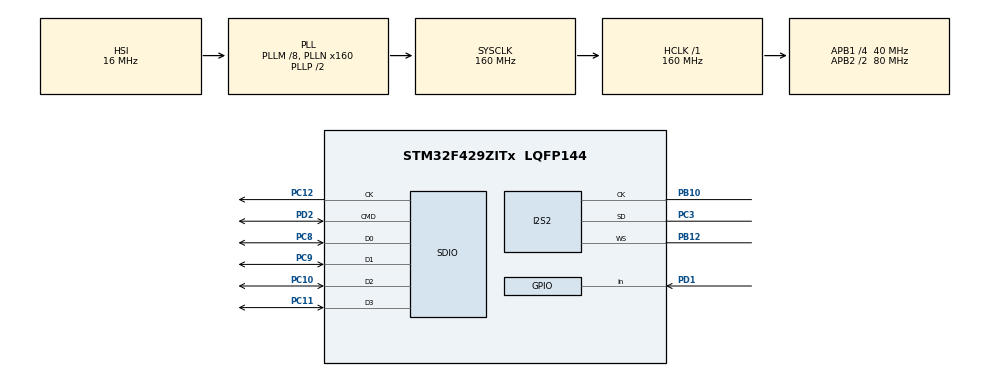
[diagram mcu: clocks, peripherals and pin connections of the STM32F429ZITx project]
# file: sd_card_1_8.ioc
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Dma.Request0=SPI2_RX
Dma.SPI2_RX.0.Direction=DMA_PERIPH_TO_MEMORY
Dma.SPI2_RX.0.FIFOMode=DMA_FIFOMODE_DISABLE
Dma.SPI2_RX.0.Instance=DMA1_Stream3
Dma.SPI2_RX.0.MemDataAlignment=DMA_MDATAALIGN_HALFWORD
Dma.SPI2_RX.0.MemInc=DMA_MINC_ENABLE
Dma.SPI2_RX.0.Mode=DMA_CIRCULAR
Dma.SPI2_RX.0.PeriphDataAlignment=DMA_PDATAALIGN_HALFWORD
Dma.SPI2_RX.0.PeriphInc=DMA_PINC_DISABLE
Dma.SPI2_RX.0.Priority=DMA_PRIORITY_LOW
FATFS.BSP.number=1
FATFS.USE_DMA_CODE_SD=0
FATFS._MAX_SS=2048
FATFS0.BSP.STBoard=false
FATFS0.BSP.api=Unknown
FATFS0.BSP.i2caddr=0
FATFS0.BSP.instance=PD1
FATFS0.BSP.ip=GPIO
FATFS0.BSP.mode=Input
FATFS0.BSP.name=Detect_SDIO
FATFS0.BSP.solution=PD1
I2S2.AudioFreq=I2S_AUDIOFREQ_32K
I2S2.DataFormat=I2S_DATAFORMAT_16B_EXTENDED
I2S2.ErrorAudioFreq=-0.26 %
I2S2.FullDuplexMode=I2S_FULLDUPLEXMODE_DISABLE
I2S2.Instance=SPI$Index
I2S2.Mode=I2S_MODE_MASTER_RX
I2S2.RealAudioFreq=31.914 KHz
I2S2.VirtualMode=I2S_MODE_MASTER
Mcu.Family=STM32F4
Mcu.Name=STM32F429ZITx
Mcu.Package=LQFP144
NVIC.DMA1_Stream3_IRQn=true\:0\:0\:false\:false\:true\:false\:true
NVIC.PriorityGroup=NVIC_PRIORITYGROUP_4
PB10.Mode=Half_Duplex_Master
PB10.Signal=I2S2_CK
PB12.Mode=Half_Duplex_Master
PB12.Signal=I2S2_WS
PC10.GPIO_PuPd=GPIO_PULLUP
PC10.Mode=SD_4_bits_Wide_bus
PC10.Signal=SDIO_D2
PC11.GPIO_PuPd=GPIO_PULLUP
PC11.Mode=SD_4_bits_Wide_bus
PC11.Signal=SDIO_D3
PC12.Mode=SD_4_bits_Wide_bus
PC12.Signal=SDIO_CK
PC3.Mode=Half_Duplex_Master
PC3.Signal=I2S2_SD
PC8.GPIO_PuPd=GPIO_PULLUP
PC8.Mode=SD_4_bits_Wide_bus
PC8.Signal=SDIO_D0
PC9.GPIO_PuPd=GPIO_PULLUP
PC9.Mode=SD_4_bits_Wide_bus
PC9.Signal=SDIO_D1
PD1.Signal=GPIO_Input
PD2.GPIO_PuPd=GPIO_PULLUP
PD2.Mode=SD_4_bits_Wide_bus
PD2.Signal=SDIO_CMD
ProjectManager.HeapSize=0x2000
ProjectManager.StackSize=0x4000
ProjectManager.TargetToolchain=STM32CubeIDE
RCC.48MHZClocksFreq_Value=45714285.71428572
RCC.AHBFreq_Value=160000000
RCC.APB1CLKDivider=RCC_HCLK_DIV4
RCC.APB1Freq_Value=40000000
RCC.APB1TimFreq_Value=80000000
RCC.APB2CLKDivider=RCC_HCLK_DIV2
RCC.APB2Freq_Value=80000000
RCC.APB2TimFreq_Value=160000000
RCC.CortexFreq_Value=160000000
RCC.HCLKFreq_Value=160000000
RCC.HSE_VALUE=8000000
RCC.HSI_VALUE=16000000
RCC.LSE_VALUE=32768
RCC.PLLM=8
RCC.PLLN=160
RCC.PLLQ=7
RCC.PLLSAIN=50
RCC.SYSCLKFreq_VALUE=160000000
RCC.SYSCLKSource=RCC_SYSCLKSOURCE_PLLCLK
RCC.VCOOutputFreq_Value=320000000
SDIO.ClockDiv=14
VP_FATFS_VS_SDIO.Mode=SDIO
board=STM32F429I-DISC1

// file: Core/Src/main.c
/* USER CODE BEGIN Header */
/**
  ******************************************************************************
  * @file           : main.c
  * @brief          : Main program body
  ******************************************************************************
  * @attention
  *
  * Copyright (c) 2023 STMicroelectronics.
  * All rights reserved.
  *
  * This software is licensed under terms that can be found in the LICENSE file
  * in the root directory of this software component.
  * If no LICENSE file comes with this software, it is provided AS-IS.
  *
  ******************************************************************************
  */
/* USER CODE END Header */
#include "main.h"
#include "fatfs.h"

/* USER CODE BEGIN Includes */
#include "stdio.h"
#include "audio_sd.h"
/* USER CODE END Includes */

I2S_HandleTypeDef hi2s2;
DMA_HandleTypeDef hdma_spi2_rx;

SD_HandleTypeDef hsd;

/* USER CODE BEGIN PV */
int16_t data_i2s[100];
volatile int16_t sample_i2s;
/* USER CODE END PV */

void SystemClock_Config(void);
static void MX_GPIO_Init(void);
static void MX_SDIO_SD_Init(void);
static void MX_DMA_Init(void);
static void MX_I2S2_Init(void);

int main(void)
{

  /* MCU Configuration--------------------------------------------------------*/

  /* Reset of all peripherals, Initializes the Flash interface and the Systick. */
  HAL_Init();

  /* Configure the system clock */
  SystemClock_Config();

  /* Initialize all configured peripherals */
  MX_GPIO_Init();
  MX_SDIO_SD_Init();
  MX_DMA_Init();
  MX_I2S2_Init();
  MX_FATFS_Init();
  /* USER CODE BEGIN 2 */
  HAL_I2S_Receive_DMA(&hi2s2, (uint8_t *)data_i2s, sizeof(data_i2s)/2);
  HAL_Delay(500);
  sd_card_init();
  /* USER CODE END 2 */

  /* Infinite loop */
  while (1)
  {

  }
}

void SystemClock_Config(void)
{
  RCC_OscInitTypeDef RCC_OscInitStruct = {0};
  RCC_ClkInitTypeDef RCC_ClkInitStruct = {0};

  /** Configure the main internal regulator output voltage
  */
  __HAL_RCC_PWR_CLK_ENABLE();
  __HAL_PWR_VOLTAGESCALING_CONFIG(PWR_REGULATOR_VOLTAGE_SCALE1);
  /** Initializes the RCC Oscillators according to the specified parameters
  * in the RCC_OscInitTypeDef structure.
  */
  RCC_OscInitStruct.OscillatorType = RCC_OSCILLATORTYPE_HSI;
  RCC_OscInitStruct.HSIState = RCC_HSI_ON;
  RCC_OscInitStruct.HSICalibrationValue = RCC_HSICALIBRATION_DEFAULT;
  RCC_OscInitStruct.PLL.PLLState = RCC_PLL_ON;
  RCC_OscInitStruct.PLL.PLLSource = RCC_PLLSOURCE_HSI;
  RCC_OscInitStruct.PLL.PLLM = 8;
  RCC_OscInitStruct.PLL.PLLN = 160;
  RCC_OscInitStruct.PLL.PLLP = RCC_PLLP_DIV2;
  RCC_OscInitStruct.PLL.PLLQ = 7;
  if (HAL_RCC_OscConfig(&RCC_OscInitStruct) != HAL_OK)
  {
    Error_Handler();
  }
  /** Initializes the CPU, AHB and APB buses clocks
  */
  RCC_ClkInitStruct.ClockType = RCC_CLOCKTYPE_HCLK|RCC_CLOCKTYPE_SYSCLK
                              |RCC_CLOCKTYPE_PCLK1|RCC_CLOCKTYPE_PCLK2;
  RCC_ClkInitStruct.SYSCLKSource = RCC_SYSCLKSOURCE_PLLCLK;
  RCC_ClkInitStruct.AHBCLKDivider = RCC_SYSCLK_DIV1;
  RCC_ClkInitStruct.APB1CLKDivider = RCC_HCLK_DIV4;
  RCC_ClkInitStruct.APB2CLKDivider = RCC_HCLK_DIV2;

  if (HAL_RCC_ClockConfig(&RCC_ClkInitStruct, FLASH_LATENCY_5) != HAL_OK)
  {
    Error_Handler();
  }
}

static void MX_I2S2_Init(void)
{

  hi2s2.Instance = SPI2;
  hi2s2.Init.Mode = I2S_MODE_MASTER_RX;
  hi2s2.Init.Standard = I2S_STANDARD_PHILIPS;
  hi2s2.Init.DataFormat = I2S_DATAFORMAT_16B_EXTENDED;
  hi2s2.Init.MCLKOutput = I2S_MCLKOUTPUT_DISABLE;
  hi2s2.Init.AudioFreq = I2S_AUDIOFREQ_32K;
  hi2s2.Init.CPOL = I2S_CPOL_LOW;
  hi2s2.Init.ClockSource = I2S_CLOCK_PLL;
  hi2s2.Init.FullDuplexMode = I2S_FULLDUPLEXMODE_DISABLE;
  if (HAL_I2S_Init(&hi2s2) != HAL_OK)
  {
    Error_Handler();
  }

}

static void MX_SDIO_SD_Init(void)
{

  hsd.Instance = SDIO;
  hsd.Init.ClockEdge = SDIO_CLOCK_EDGE_RISING;
  hsd.Init.ClockBypass = SDIO_CLOCK_BYPASS_DISABLE;
  hsd.Init.ClockPowerSave = SDIO_CLOCK_POWER_SAVE_DISABLE;
  hsd.Init.BusWide = SDIO_BUS_WIDE_1B;
  hsd.Init.HardwareFlowControl = SDIO_HARDWARE_FLOW_CONTROL_DISABLE;
  hsd.Init.ClockDiv = 14;

}

static void MX_DMA_Init(void)
{

  /* DMA controller clock enable */
  __HAL_RCC_DMA1_CLK_ENABLE();

  /* DMA interrupt init */
  /* DMA1_Stream3_IRQn interrupt configuration */
  HAL_NVIC_SetPriority(DMA1_Stream3_IRQn, 0, 0);
  HAL_NVIC_EnableIRQ(DMA1_Stream3_IRQn);

}

static void MX_GPIO_Init(void)
{
  GPIO_InitTypeDef GPIO_InitStruct = {0};

  /* GPIO Ports Clock Enable */
  __HAL_RCC_GPIOC_CLK_ENABLE();
  __HAL_RCC_GPIOB_CLK_ENABLE();
  __HAL_RCC_GPIOD_CLK_ENABLE();

  /*Configure GPIO pin : PD1 */
  GPIO_InitStruct.Pin = GPIO_PIN_1;
  GPIO_InitStruct.Mode = GPIO_MODE_INPUT;
  GPIO_InitStruct.Pull = GPIO_NOPULL;
  HAL_GPIO_Init(GPIOD, &GPIO_InitStruct);

}

/* USER CODE BEGIN 4 */
int _write(int file, char *ptr, int len)
{
	int DataIdx;

	for (DataIdx = 0; DataIdx < len; DataIdx++)
	{
		ITM_SendChar(*ptr++);
	}
	return len;
}

void HAL_I2S_RxCpltCallback(I2S_HandleTypeDef *hi2s) {
	sample_i2s = data_i2s[0];
}
/* USER CODE END 4 */

void Error_Handler(void)
{
  __disable_irq();
  while (1)
  {
  }
}
